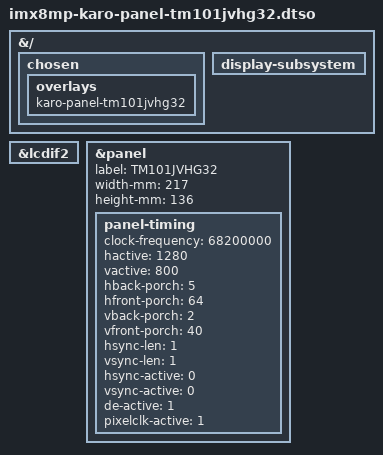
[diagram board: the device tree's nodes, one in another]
// SPDX-License-Identifier: (GPL-2.0 OR MIT)
/*
 * Copyright 2022 Lothar Waßmann <LW@KARO-electronics.de>
 *
 */

/dts-v1/;
/plugin/;

&{/} {
	chosen {
		overlays {
			karo-panel-tm101jvhg32;
		};
	};

	display-subsystem {
		status = "okay";
	};
};

&lcdif2 {
	status = "okay";
};

&panel {
	label = "TM101JVHG32";
	width-mm = <217>;
	height-mm = <136>;
	status = "okay";

	panel-timing {
		clock-frequency = <68200000>;
		hactive = <1280>;
		vactive = <800>;
		hback-porch = <5>;
		hfront-porch = <64>;
		vback-porch = <2>;
		vfront-porch = <40>;
		hsync-len = <1>;
		vsync-len = <1>;
		hsync-active = <0>;
		vsync-active = <0>;
		de-active = <1>;
		pixelclk-active = <1>;
	};
};
